# STM32MP157 register map
File version: 1.6
CPU: CM4 r0p1, little endian, no MPU, FPU, 4 interrupt priority bits
Registers are 32-bit, read-write, reset 0x0 unless marked. A register's access mark holds for its fields unless they carry their own. Offsets are from the block's base; [hi:lo] are bit positions; {n}, {i} and the like mark numbered series.

## MDMA — MDMA1
Base 0x58000000
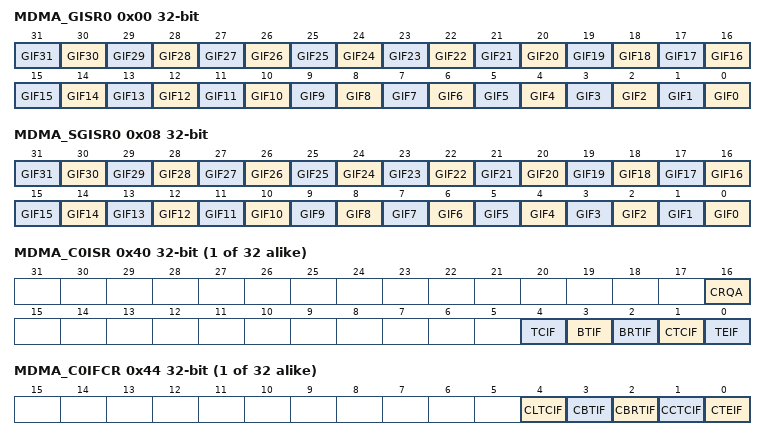
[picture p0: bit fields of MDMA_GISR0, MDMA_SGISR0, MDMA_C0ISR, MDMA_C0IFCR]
0x00 MDMA_GISR0 ro — MDMA global interrupt/status register
  [n] GIF{n} (n=0..31)
0x08 MDMA_SGISR0 ro — MDMA secure global interrupt/status register
  [n] GIF{n} (n=0..31)
{0x40+0x40*i} MDMA_C{i}ISR ro (i=0..31) — MDMA channel {i} interrupt/status register
  [16] CRQA, [4] TCIF, [3] BTIF, [2] BRTIF, [1] CTCIF, [0] TEIF
{0x44+0x40*i} MDMA_C{i}IFCR wo (i=0..31) — MDMA channel {i} interrupt flag clear register
  [4] CLTCIF, [3] CBTIF, [2] CBRTIF, [1] CCTCIF, [0] CTEIF
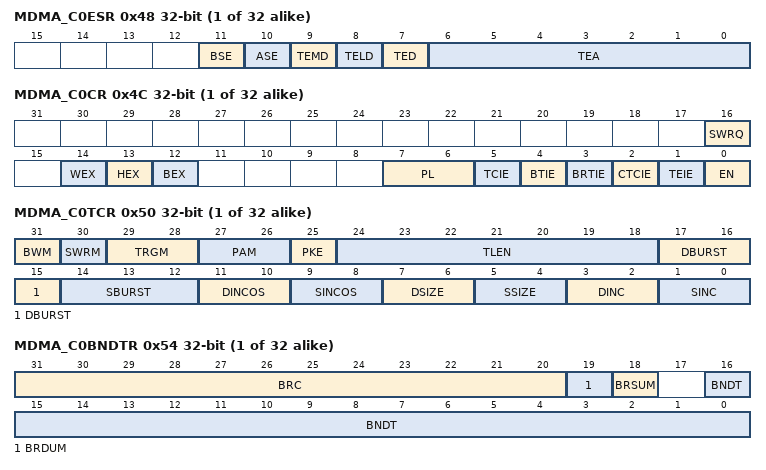
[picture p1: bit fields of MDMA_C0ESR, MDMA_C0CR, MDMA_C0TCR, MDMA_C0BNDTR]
{0x48+0x40*i} MDMA_C{i}ESR ro (i=0..31) — MDMA channel {i} error status register
  [11] BSE, [10] ASE, [9] TEMD, [8] TELD, [7] TED, [6:0] TEA
{0x4C+0x40*i} MDMA_C{i}CR access per field (i=0..31) — This register is used to control the concerned channel.
  [16] SWRQ wo, [14] WEX rw, [13] HEX rw, [12] BEX rw, [7:6] PL rw, [5] TCIE rw, [4] BTIE rw, [3] BRTIE rw, [2] CTCIE rw, [1] TEIE rw, [0] EN rw
{0x50+0x40*i} MDMA_C{i}TCR (i=0..31) — This register is used to configure the concerned channel. In Linked List mode, at the end of a block (single or last block in repeated block transfer mode), this register will be loaded from memory (from address given by current LAR[31:0] + 0x00).
  [31] BWM, [30] SWRM, [29:28] TRGM, [27:26] PAM, [25] PKE, [24:18] TLEN, [17:15] DBURST, [14:12] SBURST, [11:10] DINCOS, [9:8] SINCOS, [7:6] DSIZE, [5:4] SSIZE, [3:2] DINC, [1:0] SINC
{0x54+0x40*i} MDMA_C{i}BNDTR (i=0..31) — In Linked List mode, at the end of a block (single or last block in repeated block transfer mode), this register will be loaded from memory (from address given by current LAR[31:0] + 0x04).
  [31:20] BRC, [19] BRDUM, [18] BRSUM, [16:0] BNDT
{0x58+0x40*i} MDMA_C{i}SAR (i=0..31) — In Linked List mode, at the end of a Block (single or last Block in repeated Block transfer mode), this register will be loaded from memory (from address given by current LAR[31:0] + 0x08).
  [31:0] SAR
{0x5C+0x40*i} MDMA_C{i}DAR (i=0..31) — In Linked List mode, at the end of a block (single or last block in repeated block transfer mode), this register will be loaded from memory (from address given by current LAR[31:0] + 0x0C). M
  [31:0] DAR
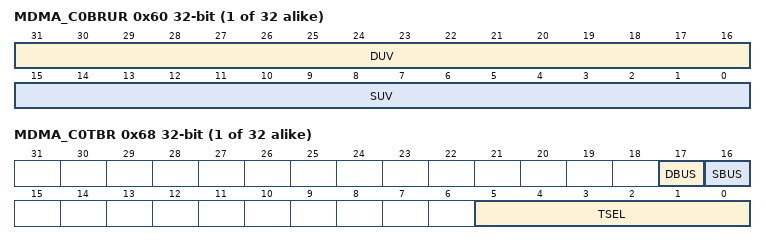
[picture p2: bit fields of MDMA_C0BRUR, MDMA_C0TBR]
{0x60+0x40*i} MDMA_C{i}BRUR (i=0..31) — In Linked List mode, at the end of a block (single or last block in repeated block transfer mode), this register will be loaded from memory (from address given by current LAR[31:0] + 0x10).
  [31:16] DUV, [15:0] SUV
{0x64+0x40*i} MDMA_C{i}LAR (i=0..31) — In Linked List mode, at the end of a block (single or last block in repeated block transfer mode), this register will be loaded from memory (from address given by current LAR[31:0] + 0x14). The new value is only taken into account after all registers are updated, for the next end of block.
  [31:0] LAR
{0x68+0x40*i} MDMA_C{i}TBR (i=0..31) — In Linked List mode, at the end of a block (single or last block in repeated block transfer mode), this register will be loaded from memory (from address given by current LAR[31:0] + 0x18).
  [17] DBUS, [16] SBUS, [5:0] TSEL
{0x70+0x40*i} MDMA_C{i}MAR (i=0..31) — In Linked List mode, at the end of a block (single or last block in repeated block transfer mode), this register will be loaded from memory (from address given by current LAR[31:0] + 0x20).
  [31:0] MAR
{0x74+0x40*i} MDMA_C{i}MDR (i=0..31) — In Linked List mode, at the end of a block (single or last block in repeated block transfer mode), this register will be loaded from memory (from address given by current LAR[31:0] + 0x24).
  [31:0] MDR

## NVIC — Nested Vectored Interrupt Controller
Base 0xE000E100
{0x0+4i} ISER{i} (i=0..3) — Interrupt Set-Enable Register
  [31:0] SETENA
0x10 ISER4 — Interrupt Set-Enable Register
{0x80+4i} ICER{i} (i=0..3) — Interrupt Clear-Enable Register
  [31:0] CLRENA
0x90 ICER4 — Interrupt Clear-Enable Register
{0x100+4i} ISPR{i} (i=0..3) — Interrupt Set-Pending Register
  [31:0] SETPEND
0x110 ISPR4 — Interrupt Set-Pending Register
{0x180+4i} ICPR{i} (i=0..3) — Interrupt Clear-Pending Register
  [31:0] CLRPEND
0x1C4 ICPR4 — Interrupt Clear-Pending Register
{0x200+4i} IABR{i} ro (i=0..3) — Interrupt Active Bit Register
  [31:0] ACTIVE
0x210 IABR4 — Interrupt Active Bit Register
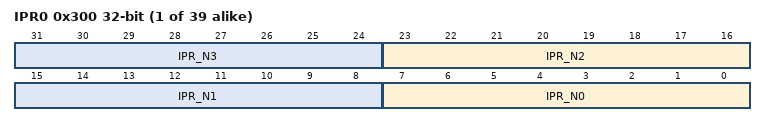
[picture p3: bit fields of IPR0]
{0x300+4i} IPR{i} (i=0..38) — Interrupt Priority Register
  [8n+7:8n] IPR_N{n} (n=0..3)
